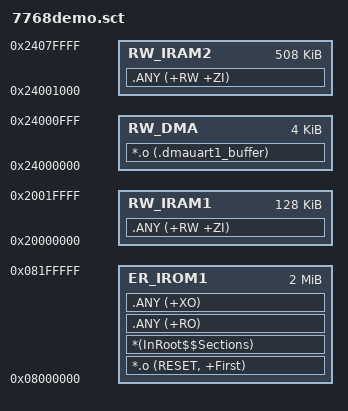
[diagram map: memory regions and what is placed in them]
; *************************************************************
; *** Scatter-Loading Description File generated by uVision ***
; *************************************************************

LR_IROM1 0x08000000 0x00200000  {    ; load region size_region
  ER_IROM1 0x08000000 0x00200000  {  ; load address = execution address
   *.o (RESET, +First)
   *(InRoot$$Sections)
   .ANY (+RO)
   .ANY (+XO)
  }
  RW_IRAM1 0x20000000 0x00020000  {  ; RW data
   .ANY (+RW +ZI)
  }
  RW_DMA 0x24000000 0x00001000  {	;串口dma缓冲区
    *.o (.dmauart1_buffer)
  }
  RW_IRAM2 0x24001000 0x0007F000  {
    .ANY (+RW +ZI)
  }
}
